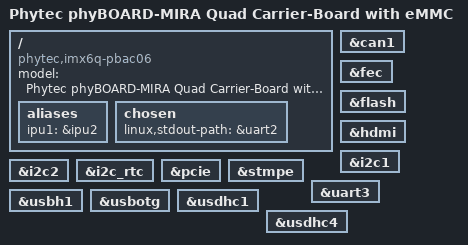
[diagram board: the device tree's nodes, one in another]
/*
 * Copyright (C) 2015 PHYTEC Messtechnik
 * Author: Christian Hemp <c.hemp@phytec.de>
 *
 * The code contained herein is licensed under the GNU General Public
 * License. You may obtain a copy of the GNU General Public License
 * Version 2 or later at the following locations:
 *
 * http://www.opensource.org/licenses/gpl-license.html
 * http://www.gnu.org/copyleft/gpl.html
 */

/dts-v1/;
#include "imx6q.dtsi"
#include "imx6qdl-phytec-phycore-som.dtsi"
#include "imx6qdl-phytec-mira.dtsi"
#include "imx6qdl-phytec-mira-peb-eval-01.dtsi"
#include "imx6qdl-phytec-mira-peb-av-02.dtsi"
#include "imx6qdl-phytec-peb-wlbt-01.dtsi"

/ {
	model = "Phytec phyBOARD-MIRA Quad Carrier-Board with eMMC";
	compatible = "phytec,imx6q-pbac06", "phytec,imx6qdl-pcm058", "fsl,imx6q";

	aliases {
		ipu1 = &ipu2;
	};

	chosen {
		linux,stdout-path = &uart2;
	};
};

&can1 {
	status = "okay";
};

&fec {
	status = "okay";
};

&flash {
	status = "okay";
};

&hdmi {
	status = "okay";
};

&i2c1 {
	status = "okay";
};

&i2c2 {
	status = "okay";
};

&i2c_rtc {
	status = "okay";
};

&pcie {
	status = "okay";
};

&stmpe {
	status = "okay";
};

&uart3 {
	status = "okay";
};

&usbh1 {
	status = "okay";
};

&usbotg {
	status = "okay";
};

&usdhc1 {
	status = "okay";
};

&usdhc4 {
	status = "okay";
};
